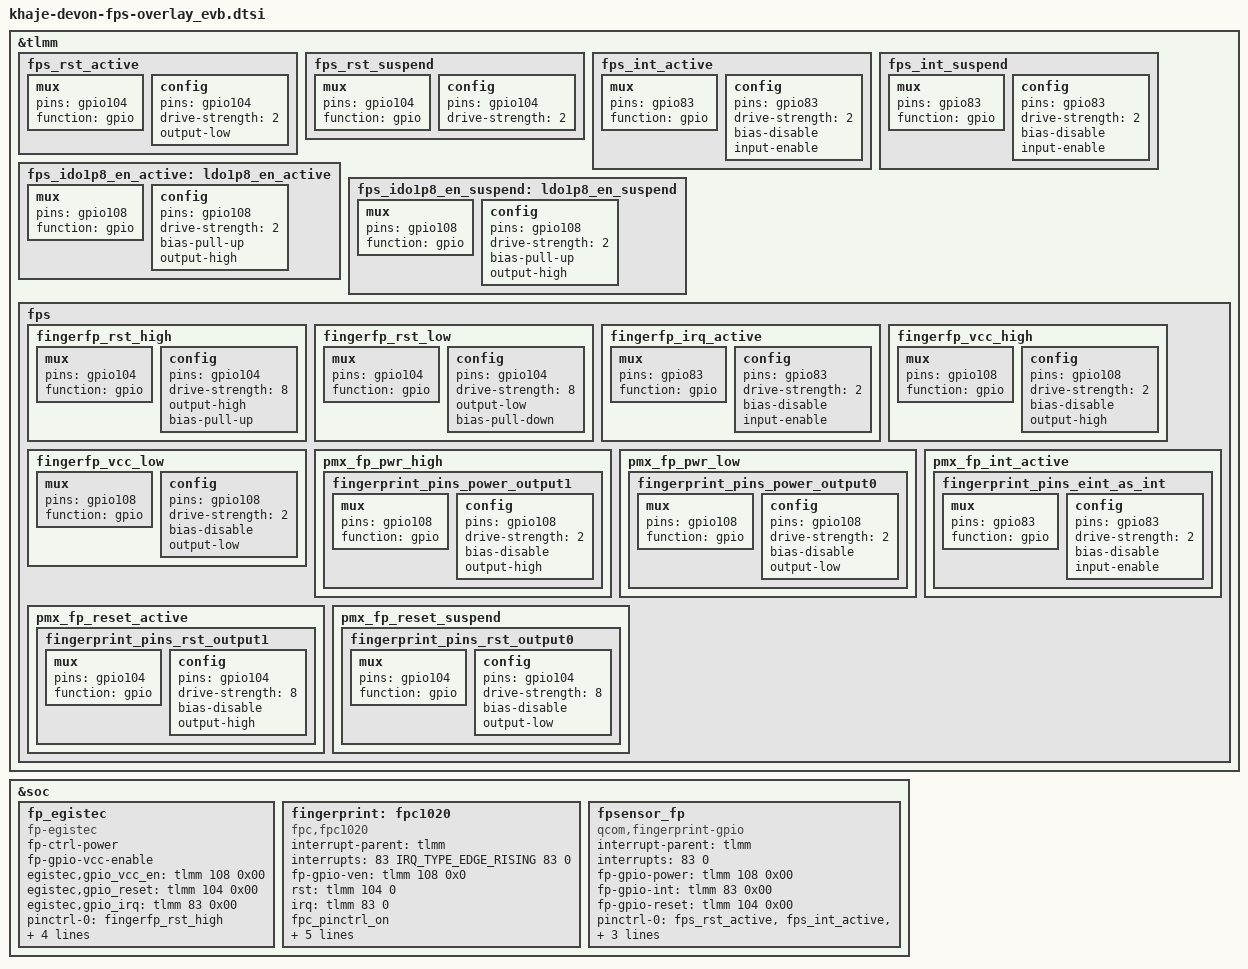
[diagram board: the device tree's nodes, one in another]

&tlmm {

        fps_rst_active: fps_rst_active {
                /* active state */
                mux {
                        pins = "gpio104";
                        function = "gpio";
                };

                config {
                        pins = "gpio104";
                        drive-strength = <2>; /* 2 MA */
                        output-low;
                };
        };

        fps_rst_suspend: fps_rst_suspend {
                /* sleep state */
                mux {
                        pins = "gpio104";
                        function = "gpio";
                };

                config {
                        pins = "gpio104";
                        drive-strength = <2>; /* 2 MA */
                };
        };

        fps_int_active: fps_int_active {
                /* active state */
                mux {
                        pins = "gpio83";
                        function = "gpio";
                };

                config {
                        pins = "gpio83";
                        drive-strength = <2>; /* 2 MA */
                        bias-disable;
                        input-enable;
                };
        };

        fps_int_suspend: fps_int_suspend {
                /* sleep state */
                mux {
                        pins = "gpio83";
                        function = "gpio";
                };

                config {
                        pins = "gpio83";
                        drive-strength = <2>; /* 2 MA */
                        bias-disable;
                        input-enable;
                };
        };

        fps_ido1p8_en_active: ldo1p8_en_active {
                /* active state */
                mux {
                        pins = "gpio108";
                        function = "gpio";
                };

                config {
                        pins = "gpio108";
                        drive-strength = <2>; /* 2 MA */
                        bias-pull-up;
                        output-high;
                };
        };

        fps_ido1p8_en_suspend: ldo1p8_en_suspend {
                /* suspend state */
                mux {
                        pins = "gpio108";
                        function = "gpio";
                };

                config {
                        pins = "gpio108";
                        drive-strength = <2>; /* 2 MA */
                        bias-pull-up;
                        output-high;
                };
        };

	fps {

		fingerfp_rst_high: fingerfp_rst_high {
			mux {
				pins = "gpio104";
				function = "gpio";
			};

			config {
				pins = "gpio104";
				drive-strength = <8>;
				output-high;
				bias-pull-up;
			};
		};

		fingerfp_rst_low: fingerfp_rst_low {
			mux {
				pins = "gpio104";
				function = "gpio";
			};
			config {
				pins = "gpio104";
				drive-strength = <8>;
				output-low;
				bias-pull-down;
			};
		};

		fingerfp_irq_active: fingerfp_irq_active {
			mux {
				pins = "gpio83";
				function = "gpio";
			};
			config {
				pins = "gpio83";
				drive-strength = <2>;
				bias-disable;
				input-enable;
			};
		};

		fingerfp_vcc_high: fingerfp_vcc_high {
			mux {
				pins = "gpio108";
				function = "gpio";
			};

			config {
				pins = "gpio108";
				drive-strength = <2>;
				bias-disable;
				output-high;
			};
		};
	
		fingerfp_vcc_low: fingerfp_vcc_low {
			mux {
				pins = "gpio108";
				function = "gpio";
			};

			config {
				pins = "gpio108";
				drive-strength = <2>;
				bias-disable;
				output-low;
			};
		};

		
		pmx_fp_pwr_high {
			fingerprint_pins_power_output1: fingerprint_pins_power_output1 {
				mux {
					pins = "gpio108";
					function = "gpio";
				};

				config {
					pins = "gpio108";
					drive-strength = <2>;
					bias-disable;
					output-high;
				};
			};
		};

		pmx_fp_pwr_low {
			fingerprint_pins_power_output0: fingerprint_pins_power_output0 {
				mux {
					pins = "gpio108";
					function = "gpio";
				};

				config {
					pins = "gpio108";
					drive-strength = <2>;
					bias-disable;
					output-low;
				};
			};
		};

		pmx_fp_int_active {

			fingerprint_pins_eint_as_int: fingerprint_pins_eint_as_int
			{
				mux {
					pins = "gpio83";
					function = "gpio";
				};

				config {
					pins = "gpio83";
					drive-strength = <2>;
					bias-disable;
					input-enable;
				};
			};
		};

		pmx_fp_reset_active {
			fingerprint_pins_rst_output1: fingerprint_pins_rst_output1 {
				mux {
					pins = "gpio104";
					function = "gpio";
				};

				config {
					pins = "gpio104";
					drive-strength = <8>;
					bias-disable;
					output-high;
				};
			};
		};

		pmx_fp_reset_suspend {
			fingerprint_pins_rst_output0: fingerprint_pins_rst_output0 {
				mux {
					pins = "gpio104";
					function = "gpio";
				};

				config {
					pins = "gpio104";
					drive-strength = <8>;
					bias-disable;
					output-low;
				};
			};
		};
	};
};

&soc {

	fp_egistec {
		status = "ok";
		compatible = "fp-egistec";
		fp-ctrl-power;
		fp-gpio-vcc-enable;
		egistec,gpio_vcc_en = <&tlmm 108 0x00>;
		egistec,gpio_reset = <&tlmm 104 0x00>;
		egistec,gpio_irq = <&tlmm 83 0x00>;
		pinctrl-names = "egis_rst_high", "egis_rst_low", "egis_irq_active", "egis_vcc_high", "egis_vcc_low";
		pinctrl-0 = <&fingerfp_rst_high>;
		pinctrl-1 = <&fingerfp_rst_low>;
		pinctrl-2 = <&fingerfp_irq_active>;
		pinctrl-3 = <&fingerfp_vcc_high>;
		pinctrl-4 = <&fingerfp_vcc_low>;
	};

	fingerprint: fpc1020 {
                status = "ok";
		compatible = "fpc,fpc1020";
		interrupt-parent = <&tlmm>;
		interrupts = <83 IRQ_TYPE_EDGE_RISING 83 0>;
                fp-gpio-ven = <&tlmm 108 0x0>;
		rst = <&tlmm 104 0>;
		irq = <&tlmm 83 0>;
		fpc_pinctrl_on;
	        pinctrl-names = "fpc_vdd_on","fpc_vdd_of","fpc_rst_lo","fpc_rst_hi","fpc_irq_en";
		pinctrl-0 = <&fingerprint_pins_power_output1>;
		pinctrl-1 = <&fingerprint_pins_power_output0>;
		pinctrl-2 = <&fingerprint_pins_rst_output0>;
		pinctrl-3 = <&fingerprint_pins_rst_output1>;
		pinctrl-4 = <&fingerprint_pins_eint_as_int>;
	};

        fpsensor_fp {
                //status = "/chosen", "mmi,fps", "true";
                status = "ok";
                compatible = "qcom,fingerprint-gpio";
                interrupt-parent = <&tlmm>;
                interrupts = <83 0>;
                fp-gpio-power = <&tlmm 108 0x00>;
                fp-gpio-int    = <&tlmm 83 0x00>;
                fp-gpio-reset = <&tlmm 104 0x00>;
                pinctrl-names = "default", "suspend";
                pinctrl-0 = <&fps_rst_active &fps_int_active &fps_ido1p8_en_active>;
                pinctrl-1 = <&fps_rst_suspend &fps_int_suspend &fps_ido1p8_en_suspend>;
        };

/*
	focalfp_ft9362 {
		status = "ok";
		compatible = "focaltech,fingerprint";
		interrupt-parent = <&tlmm>;
		interrupts = <83 0x0>;
		fp,reset_gpio = <&tlmm 3 0>;
		fp,irq_gpio = <&tlmm 83 0>;
		fp,vdd_gpio = <&tlmm 54 0>;

		pinctrl-names = "fpsensor_finger_power_high","fpsensor_finger_power_low","fpsensor_finger_rst_low","fpsensor_finger_rst_high","fpsensor_eint_as_int";
		pinctrl-0 = <&fingerprint_pins_power_output1>;
		pinctrl-1 = <&fingerprint_pins_power_output0>;
		pinctrl-2 = <&fingerprint_pins_rst_output0>;
		pinctrl-3 = <&fingerprint_pins_rst_output1>;
		pinctrl-4 = <&fingerprint_pins_eint_as_int>;
	};
*/
};
